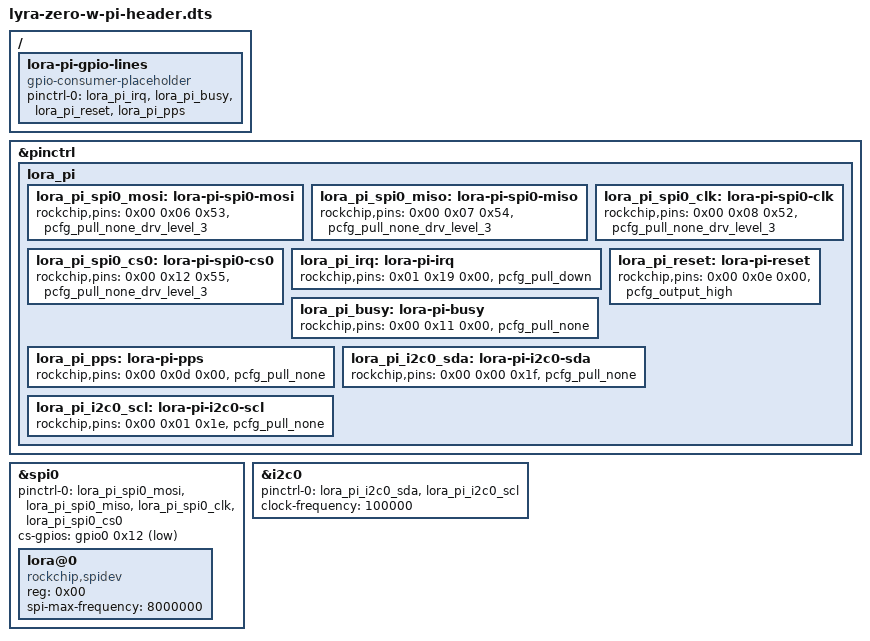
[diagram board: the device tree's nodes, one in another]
/dts-v1/;
/plugin/;

/*
 * Remaps the Lyra Zero W's 40-pin header to match the Raspberry Pi family's
 * (Zero 2W layout) SPI0 + LoRa-HAT control lines (meshadv-style SX126x
 * pinout) AND user I2C bus, so Pi-designed HATs (LoRa radio, RTC, power
 * monitor, etc.) plug in and work unmodified. This is deliberately scoped
 * to match the Pi header broadly, not just what one specific HAT needs, so
 * third-party HAT designs built against this pinout aren't Lyra-specific.
 *
 * This is the DEFAULT overlay for the gold image. It is mutually exclusive
 * with lyra-zero-w-station-g3.dts (NOT both): that overlay claims pin16 as
 * an output (Station G3 RXEN/LNA_EN, active-low) instead of as an input
 * here. Switching is handled by /usr/local/sbin/lyra-hat-pinmux, called
 * by the first-boot wizard and the reticulum-mesh bringup. See
 * dts-overlay/README.md for the full rationale.
 *
 * All values below were extracted from the LIVE board's compiled device tree
 * (`dtc -I fs -O dts /proc/device-tree` over SSH to lyra-node / 10.0.0.200)
 * plus the physical-pin<->RM_IO mapping confirmed against the official
 * Luckfox pinout diagram and cross-checked with josh's own RMIO/pinctrl
 * table for this board. No placeholder/guessed values remain.
 *
 * Physical pin -> function -> RM_IO -> chip GPIO pin -> rockchip,pins value
 *   19 MOSI    -> RM_IO6  -> GPIO0_A6 (chip 6)  -> <0x00 0x06 0x53 ...>
 *   21 MISO    -> RM_IO7  -> GPIO0_A7 (chip 7)  -> <0x00 0x07 0x54 ...>
 *   23 SCLK    -> RM_IO8  -> GPIO0_B0 (chip 8)  -> <0x00 0x08 0x52 ...>
 *   40 CSN0/CS -> RM_IO18 -> GPIO0_C2 (chip 18) -> <0x00 0x12 0x55 ...>
 *   36 IRQ     -> RM_IO29 -> GPIO1_D1 (chip 57) -> plain GPIO input (mux 0)
 *   38 BUSY    -> RM_IO17 -> GPIO0_C1 (chip 17) -> plain GPIO input (mux 0)
 *   12 RESET   -> RM_IO14 -> GPIO0_B6 (chip 14) -> plain GPIO output (mux 0)
 *    3 I2C_SDA -> RM_IO0  -> GPIO0_A0 (chip 0)  -> <0x00 0x00 0x1f ...>
 *    5 I2C_SCL -> RM_IO1  -> GPIO0_A1 (chip 1)  -> <0x00 0x01 0x1e ...>
 *
 * Pin 16 (RM_IO13 = GPIO0_B5 = bank0 offset 0x0d) is reserved here for the
 * MeshAdv + GPS HAT combo's PPS INPUT (a u-blox NEO-M8N/M9N GPS HAT
 * typically stacks on top of the LoRa HAT on the Pi header, with its PPS
 * output wired to physical pin 16). We pinmux it as a plain GPIO input
 * here; userspace reads it via libgpiod / NMEA clients. The Station G3
 * overlay does NOT claim pin16 this way - it instead drives it as the
 * RXEN/LNA_EN output - see lyra-zero-w-station-g3.dts.
 *   16 PPS     -> RM_IO13 -> GPIO0_B5 (chip 13) -> plain GPIO input (mux 0)
 *
 * Physical pins 3/5 match the Raspberry Pi's user-facing "I2C1" bus position
 * (used by nearly every off-the-shelf RTC/power-monitor HAT, e.g. DS3231,
 * PCF8563, INA3221 breakouts). Routed here to this board's i2c0 controller
 * (i2c@ff040000) - the bus NUMBER doesn't need to match the Pi's naming,
 * only the physical pin POSITION does, since that's what a HAT physically
 * plugs into. i2c2 (ff060000) is already in use on this board for the
 * touchscreen controller - do not repurpose it. i2c1 (ff050000) is free if
 * a second bus is ever needed.
 *
 * SPI0 (spi@ff120000) is a general-purpose SPI controller distinct from the
 * boot flash controller (fspi@ff488000, a separate node) - confirmed safe to
 * repurpose. Its stock/default pinctrl-0 uses a different, internal set of
 * fixed pins (bank0 pin19/15/16-18, mux=2) for some other on-board use; this
 * overlay REPLACES that default with the header/RM_IO-routed pins instead.
 */

/ {
	fragment@0 {
		target = <&pinctrl>;
		__overlay__ {
			/* Pin groups must live inside an intermediate named subnode, not
			 * directly as children of &pinctrl - confirmed by testing on the
			 * live board ("unable to find group for node ..." in dmesg even
			 * after fixing the one-tuple-per-node issue). Matches the nesting
			 * pattern used by both this board's own base tree (rm_io6 { rm-io6-
			 * spi0-mosi {...}; }) and josh's known-working femtofox config
			 * (spi0 { spi0m0_clk {...}; }). */
			lora_pi {
				lora_pi_spi0_mosi: lora-pi-spi0-mosi {
					rockchip,pins = <0x00 0x06 0x53 &pcfg_pull_none_drv_level_3>; /* pin19 MOSI (RM_IO6) */
				};
				lora_pi_spi0_miso: lora-pi-spi0-miso {
					rockchip,pins = <0x00 0x07 0x54 &pcfg_pull_none_drv_level_3>; /* pin21 MISO (RM_IO7) */
				};
				lora_pi_spi0_clk: lora-pi-spi0-clk {
					rockchip,pins = <0x00 0x08 0x52 &pcfg_pull_none_drv_level_3>; /* pin23 SCLK (RM_IO8) */
				};
				lora_pi_spi0_cs0: lora-pi-spi0-cs0 {
					rockchip,pins = <0x00 0x12 0x55 &pcfg_pull_none_drv_level_3>; /* pin40 CSN0 (RM_IO18) */
				};

				lora_pi_irq: lora-pi-irq {
					/* pin36, GPIO1_D1 (chip 57 = bank1 offset 25 = 0x19), plain GPIO input */
					rockchip,pins = <0x01 0x19 0x00 &pcfg_pull_down>;
				};

				lora_pi_busy: lora-pi-busy {
					/* pin38, GPIO0_C1 (chip 17 = bank0 offset 17 = 0x11), plain GPIO input */
					rockchip,pins = <0x00 0x11 0x00 &pcfg_pull_none>;
				};

				lora_pi_reset: lora-pi-reset {
					/* pin12, GPIO0_B6 (chip 14 = bank0 offset 14 = 0x0e), plain GPIO output, default high (not in reset) */
					rockchip,pins = <0x00 0x0e 0x00 &pcfg_output_high>;
				};

				lora_pi_pps: lora-pi-pps {
					/* pin16 GPS PPS INPUT (MeshAdv + GPS HAT combo). GPIO0_B5
					 * (chip 13 = bank0 offset 13 / RM_IO13). Plain GPIO input,
					 * no pull. ONLY this overlay claims pin16 - the Station G3
					 * overlay claims the SAME pin as an RXEN output instead and
					 * is mutually exclusive with this one. lyra-hat-pinmux picks
					 * which .dtbo gets loaded. */
					rockchip,pins = <0x00 0x0d 0x00 &pcfg_pull_none>;
				};

				lora_pi_i2c0_sda: lora-pi-i2c0-sda {
					/* pin3 I2C_SDA, GPIO0_A0 (RM_IO0) */
					rockchip,pins = <0x00 0x00 0x1f &pcfg_pull_none>;
				};
				lora_pi_i2c0_scl: lora-pi-i2c0-scl {
					/* pin5 I2C_SCL, GPIO0_A1 (RM_IO1) */
					rockchip,pins = <0x00 0x01 0x1e &pcfg_pull_none>;
				};
			};
		};
	};

	fragment@1 {
		target = <&spi0>; /* spi@ff120000 */
		__overlay__ {
			status = "okay";
			pinctrl-names = "default";
			pinctrl-0 = <&lora_pi_spi0_mosi &lora_pi_spi0_miso &lora_pi_spi0_clk &lora_pi_spi0_cs0>;
			#address-cells = <0x01>;
			#size-cells = <0x00>;
			/* Required per josh's own known-working femtofox (rv1103, same
			 * rockchip,rk3066-spi-family driver) config: the CS pin must also
			 * be declared as a GPIO the driver toggles in software, in addition
			 * to being pinmux'd to the hardware CSN0 function above. Without
			 * this the spi_master silently never registers (no dmesg output at
			 * all) - confirmed by testing on the live board.
			 * pin40 CSN0 = GPIO0_C2 (chip 18 = bank0 offset 18 = 0x12), active-low.
			 */
			cs-gpios = <&gpio0 0x12 0x01>;

			lora@0 {
				/* Userspace driver (reticulum-hat-mod's SX126xInterface.py) talks
				 * over /dev/spidevX.Y. Matches femtofox's known-working compatible
				 * string for this driver family (generic "spidev" alone did not
				 * bind on this vendor kernel).
				 */
				compatible = "rockchip,spidev";
				reg = <0x00>;
				spi-max-frequency = <8000000>;
				status = "okay";
			};
		};
	};

	fragment@2 {
		target-path = "/";
		__overlay__ {
			lora-pi-gpio-lines {
				compatible = "gpio-consumer-placeholder"; /* documentation only, not a real binding */
				/* IRQ/BUSY/RESET are consumed directly by SX126xInterface.py via
				 * gpiod/sysfs using these GPIO numbers - no kernel driver needed:
				 *   IRQ   (pin36): gpiochip1 line 25 (bank1 offset 25 / GPIO1_D1)
				 *   BUSY  (pin38): gpiochip0 line 17 (bank0 offset 17 / GPIO0_C1)
				 *   RESET (pin12): gpiochip0 line 14 (bank0 offset 14 / GPIO0_B6)
				 * PPS (pin16) is read directly by userspace gpsd/NMEA clients via
				 *   libgpiod (gpiochip0 line 13 = bank0 offset 13 / GPIO0_B5).
				 * pinctrl-0 above just claims/mux's them; nothing else to declare.
				 */
				pinctrl-names = "default";
				pinctrl-0 = <&lora_pi_irq &lora_pi_busy &lora_pi_reset &lora_pi_pps>;
				status = "okay";
			};
		};
	};

	fragment@3 {
		target = <&i2c0>; /* i2c@ff040000 - matches Pi physical pins 3/5 (I2C1 position) */
		__overlay__ {
			status = "okay";
			pinctrl-names = "default";
			pinctrl-0 = <&lora_pi_i2c0_sda &lora_pi_i2c0_scl>;
			#address-cells = <0x01>;
			#size-cells = <0x00>;
			clock-frequency = <100000>;
			/* Add RTC / INA3221 / other I2C peripheral child nodes here once a
			 * specific chip is chosen, e.g.:
			 *   rtc@68 { compatible = "dallas,ds3231"; reg = <0x68>; };
			 *   ina3221@40 { compatible = "ti,ina3221"; reg = <0x40>; */
			/* Until then this just brings up /dev/i2c-N so i2c-tools
			 * (i2cdetect/i2cget/i2cset, already installed by the build
			 * script) can probe whatever's actually attached. */
		};
	};
};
